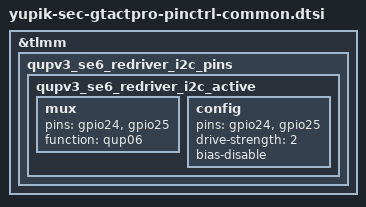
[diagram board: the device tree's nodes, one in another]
/* Copyright (c) 2021, The Linux Foundation. All rights reserved.
 *
 * This program is free software; you can redistribute it and/or modify
 * it under the terms of the GNU General Public License version 2 and
 * only version 2 as published by the Free Software Foundation.
 *
 * This program is distributed in the hope that it will be useful,
 * but WITHOUT ANY WARRANTY; without even the implied warranty of
 * MERCHANTABILITY or FITNESS FOR A PARTICULAR PURPOSE.  See the
 * GNU General Public License for more details.
 */

&tlmm {
	/* SE 6 pin mappings */
	qupv3_se6_redriver_i2c_pins: qupv3_se6_redriver_i2c_pins {
		qupv3_se6_redriver_i2c_active: qupv3_se6_redriver_i2c_active {
			mux {
				pins = "gpio24", "gpio25";
				function = "qup06";
			};

			config {
				pins = "gpio24", "gpio25";
				drive-strength = <2>;
				bias-disable; /* No PULL */
			};
		};
	};
};


